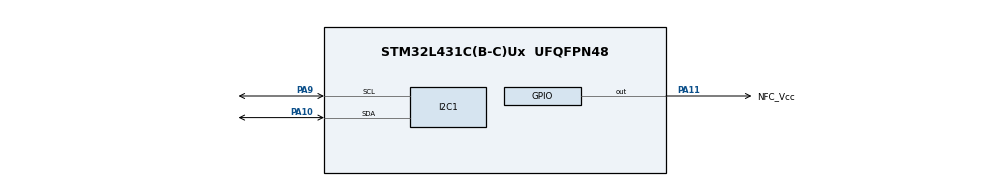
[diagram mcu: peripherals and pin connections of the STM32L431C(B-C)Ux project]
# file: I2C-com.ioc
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I2C1.Timing=0x00100D14
Mcu.Family=STM32L4
Mcu.Name=STM32L431C(B-C)Ux
Mcu.Package=UFQFPN48
NVIC.PriorityGroup=NVIC_PRIORITYGROUP_4
PA10.Mode=I2C
PA10.Signal=I2C1_SDA
PA11.GPIO_Label=NFC_Vcc
PA11.Signal=GPIO_Output
PA9.Mode=I2C
PA9.Signal=I2C1_SCL
ProjectManager.HeapSize=0x200
ProjectManager.StackSize=0x400
ProjectManager.TargetToolchain=STM32CubeIDE
RCC.HSE_VALUE=8000000
RCC.HSI48_VALUE=48000000
RCC.HSI_VALUE=16000000
RCC.LSE_VALUE=32768
RCC.MSI_VALUE=4000000
RCC.VCOOutputFreq_Value=32000000
board=custom

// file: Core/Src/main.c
/* USER CODE BEGIN Header */
/**
  ******************************************************************************
  * @file           : main.c
  * @brief          : Main program body
  ******************************************************************************
  * @attention
  *
  * Copyright (c) 2025 STMicroelectronics.
  * All rights reserved.
  *
  * This software is licensed under terms that can be found in the LICENSE file
  * in the root directory of this software component.
  * If no LICENSE file comes with this software, it is provided AS-IS.
  *
  ******************************************************************************
  */
/* USER CODE END Header */
#include "main.h"

/* USER CODE BEGIN PD */
#define NTP_ADDRESS  0xA8
//SCB->VTOR = FLASH_BASE | 0x00000000U;

/* USER CODE END PD */

I2C_HandleTypeDef hi2c1;

/* USER CODE BEGIN PV */
uint8_t tx_buffer[6] = {0x00, 0x02, 0xBA, 0xDB, 0x01, 0xBB};
uint8_t rx_address[2] = {0x00, 0x02};
uint8_t rx_buffer[4];

HAL_StatusTypeDef  status = HAL_OK;

/* USER CODE END PV */

void SystemClock_Config(void);
static void MX_GPIO_Init(void);
static void MX_I2C1_Init(void);
/* USER CODE BEGIN PFP */

void NTP_Write_eeprom(uint8_t BL_AD1, uint8_t BL_AD0, uint8_t DATA0, uint8_t DATA1, uint8_t DATA2, uint8_t DATA3);
void NTP_Read_eeprom(uint8_t BL_AD1, uint8_t BL_AD0, uint8_t* target);

/* USER CODE END PFP */

int main(void)
{

  /* MCU Configuration--------------------------------------------------------*/

  /* Reset of all peripherals, Initializes the Flash interface and the Systick. */
  HAL_Init();

  /* Configure the system clock */
  SystemClock_Config();

  /* Initialize all configured peripherals */
  MX_GPIO_Init();
  MX_I2C1_Init();
  /* USER CODE BEGIN 2 */

  HAL_GPIO_WritePin(NFC_Vcc_GPIO_Port, NFC_Vcc_Pin, 1);
  HAL_Delay(20);
  NTP_Write_eeprom(0x10, 0x3D, 0b00001101,0x00,0x01,0x00); //V_EH
  HAL_Delay(20);
  NTP_Write_eeprom(0x10, 0x37, 0b00001000,0x00,0xFF,0x00); //EH_MODE
  HAL_Delay(20);
  NTP_Read_eeprom(0x00, 0x02, rx_buffer);
  HAL_GPIO_WritePin(NFC_Vcc_GPIO_Port, NFC_Vcc_Pin, 0);
  HAL_Delay(50);

  ///HAL_SuspendTick();
  ///HAL_PWREx_EnterSTOP2Mode(PWR_SLEEPENTRY_WFI);
  ///HAL_ResumeTick();

  /* USER CODE END 2 */

  /* Infinite loop */
  while (1)
  {

    /* USER CODE BEGIN 3 */
	  HAL_GPIO_WritePin(NFC_Vcc_GPIO_Port, NFC_Vcc_Pin, 1);
	   HAL_Delay(20);
	   NTP_Write_eeprom(0x00, 0x02, 0b00001101,0xAA,0x01,0xBB);
	   HAL_Delay(20);
	   NTP_Read_eeprom(0x00, 0x02, rx_buffer);
	   HAL_GPIO_WritePin(NFC_Vcc_GPIO_Port, NFC_Vcc_Pin, 0);
	   HAL_Delay(1000);

  }
  /* USER CODE END 3 */
}

void SystemClock_Config(void)
{
  RCC_OscInitTypeDef RCC_OscInitStruct = {0};
  RCC_ClkInitTypeDef RCC_ClkInitStruct = {0};

  /** Configure the main internal regulator output voltage
  */
  if (HAL_PWREx_ControlVoltageScaling(PWR_REGULATOR_VOLTAGE_SCALE1) != HAL_OK)
  {
    Error_Handler();
  }

  /** Initializes the RCC Oscillators according to the specified parameters
  * in the RCC_OscInitTypeDef structure.
  */
  RCC_OscInitStruct.OscillatorType = RCC_OSCILLATORTYPE_MSI;
  RCC_OscInitStruct.MSIState = RCC_MSI_ON;
  RCC_OscInitStruct.MSICalibrationValue = 0;
  RCC_OscInitStruct.MSIClockRange = RCC_MSIRANGE_6;
  RCC_OscInitStruct.PLL.PLLState = RCC_PLL_NONE;
  if (HAL_RCC_OscConfig(&RCC_OscInitStruct) != HAL_OK)
  {
    Error_Handler();
  }

  /** Initializes the CPU, AHB and APB buses clocks
  */
  RCC_ClkInitStruct.ClockType = RCC_CLOCKTYPE_HCLK|RCC_CLOCKTYPE_SYSCLK
                              |RCC_CLOCKTYPE_PCLK1|RCC_CLOCKTYPE_PCLK2;
  RCC_ClkInitStruct.SYSCLKSource = RCC_SYSCLKSOURCE_MSI;
  RCC_ClkInitStruct.AHBCLKDivider = RCC_SYSCLK_DIV1;
  RCC_ClkInitStruct.APB1CLKDivider = RCC_HCLK_DIV1;
  RCC_ClkInitStruct.APB2CLKDivider = RCC_HCLK_DIV1;

  if (HAL_RCC_ClockConfig(&RCC_ClkInitStruct, FLASH_LATENCY_0) != HAL_OK)
  {
    Error_Handler();
  }
  SCB->VTOR = FLASH_BASE | 0x00000000U;
}

static void MX_I2C1_Init(void)
{

  hi2c1.Instance = I2C1;
  hi2c1.Init.Timing = 0x00100D14;
  hi2c1.Init.OwnAddress1 = 0;
  hi2c1.Init.AddressingMode = I2C_ADDRESSINGMODE_7BIT;
  hi2c1.Init.DualAddressMode = I2C_DUALADDRESS_DISABLE;
  hi2c1.Init.OwnAddress2 = 0;
  hi2c1.Init.OwnAddress2Masks = I2C_OA2_NOMASK;
  hi2c1.Init.GeneralCallMode = I2C_GENERALCALL_DISABLE;
  hi2c1.Init.NoStretchMode = I2C_NOSTRETCH_DISABLE;
  if (HAL_I2C_Init(&hi2c1) != HAL_OK)
  {
    Error_Handler();
  }

  /** Configure Analogue filter
  */
  if (HAL_I2CEx_ConfigAnalogFilter(&hi2c1, I2C_ANALOGFILTER_ENABLE) != HAL_OK)
  {
    Error_Handler();
  }

  /** Configure Digital filter
  */
  if (HAL_I2CEx_ConfigDigitalFilter(&hi2c1, 0) != HAL_OK)
  {
    Error_Handler();
  }

}

static void MX_GPIO_Init(void)
{
  GPIO_InitTypeDef GPIO_InitStruct = {0};

  /* GPIO Ports Clock Enable */
  __HAL_RCC_GPIOA_CLK_ENABLE();

  /*Configure GPIO pin Output Level */
  HAL_GPIO_WritePin(NFC_Vcc_GPIO_Port, NFC_Vcc_Pin, GPIO_PIN_RESET);

  /*Configure GPIO pin : NFC_Vcc_Pin */
  GPIO_InitStruct.Pin = NFC_Vcc_Pin;
  GPIO_InitStruct.Mode = GPIO_MODE_OUTPUT_PP;
  GPIO_InitStruct.Pull = GPIO_NOPULL;
  GPIO_InitStruct.Speed = GPIO_SPEED_FREQ_LOW;
  HAL_GPIO_Init(NFC_Vcc_GPIO_Port, &GPIO_InitStruct);

}

/* USER CODE BEGIN 4 */

void NTP_Write_eeprom(uint8_t BL_AD1, uint8_t BL_AD0, uint8_t DATA0, uint8_t DATA1, uint8_t DATA2, uint8_t DATA3){

	uint8_t tx_buff[6] = {BL_AD1, BL_AD0, DATA0, DATA1, DATA2, DATA3};

	status = HAL_I2C_Master_Transmit(&hi2c1, NTP_ADDRESS, tx_buff, 6, 2);

}

void NTP_Read_eeprom(uint8_t BL_AD1, uint8_t BL_AD0, uint8_t* target){

	uint8_t rx_add[2] = {BL_AD1, BL_AD0};

	status = HAL_I2C_Master_Transmit(&hi2c1, NTP_ADDRESS, rx_add, 2, 2);
	status = HAL_I2C_Master_Receive(&hi2c1, NTP_ADDRESS, target, 4, 1);
}

/* USER CODE END 4 */

void Error_Handler(void)
{
  __disable_irq();
  while (1)
  {
  }
}
